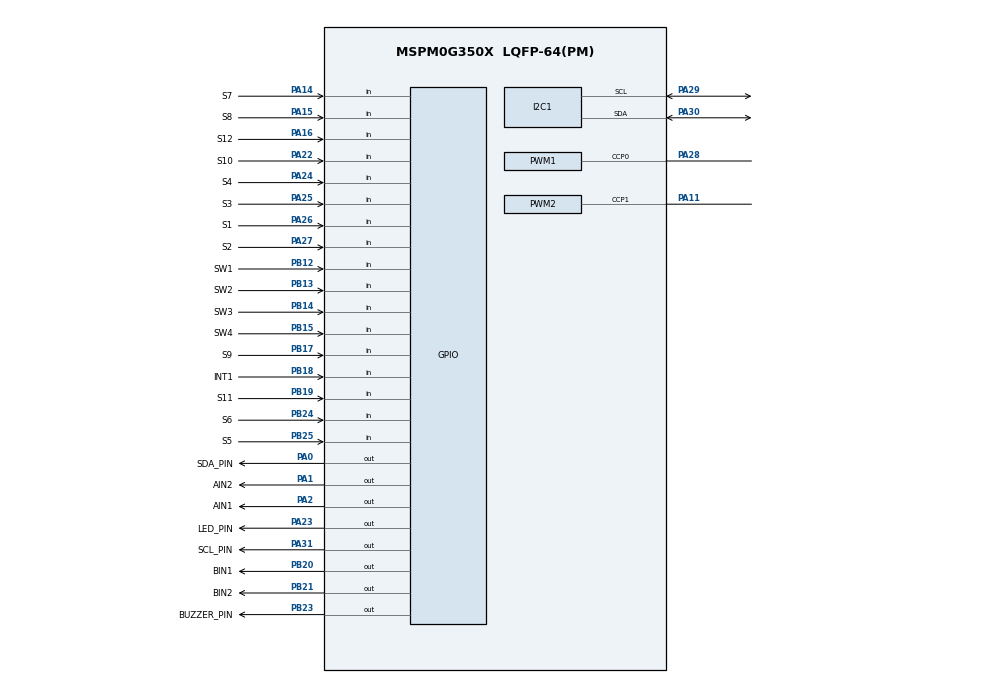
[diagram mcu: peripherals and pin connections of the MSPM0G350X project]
/**
 * @cliArgs --device "MSPM0G350X" --part "Default" --package "LQFP-64(PM)" --product "mspm0_sdk@2.11.00.07"
 * @versions {"tool":"1.26.2+4477"}
 */

/**
 * Import the modules used in this configuration.
 */
const GPIO   = scripting.addModule("/ti/driverlib/GPIO", {}, false);
const GPIO1  = GPIO.addInstance();
const GPIO2  = GPIO.addInstance();
const GPIO3  = GPIO.addInstance();
const GPIO4  = GPIO.addInstance();
const GPIO5  = GPIO.addInstance();
const GPIO7  = GPIO.addInstance();
const GPIO8  = GPIO.addInstance();
const I2C    = scripting.addModule("/ti/driverlib/I2C", {}, false);
const I2C1   = I2C.addInstance();
const PWM    = scripting.addModule("/ti/driverlib/PWM", {}, false);
const PWM1   = PWM.addInstance();
const PWM2   = PWM.addInstance();
const SYSCTL = scripting.addModule("/ti/driverlib/SYSCTL");

/**
 * Write custom configuration values to the imported modules.
 */
GPIO1.$name                          = "LED";
GPIO1.associatedPins[0].$name        = "LED_PIN";
GPIO1.associatedPins[0].pin.$assign  = "PA23";

const Board = scripting.addModule("/ti/driverlib/Board", {}, false);

GPIO2.$name                         = "BUZZER";
GPIO2.associatedPins[0].$name       = "BUZZER_PIN";
GPIO2.associatedPins[0].pin.$assign = "PB23";

GPIO3.$name                         = "OLED_SCL";
GPIO3.associatedPins[0].$name       = "SCL_PIN";
GPIO3.associatedPins[0].pin.$assign = "PA31";

GPIO4.$name                         = "OLED_SDA";
GPIO4.associatedPins[0].$name       = "SDA_PIN";
GPIO4.associatedPins[0].pin.$assign = "PA0";

GPIO5.$name = "GRAY";
GPIO5.associatedPins.create(12);
GPIO5.associatedPins[0].$name  = "S1";
GPIO5.associatedPins[0].direction = "INPUT";
GPIO5.associatedPins[0].pin.$assign = "PA26";
GPIO5.associatedPins[1].$name  = "S2";
GPIO5.associatedPins[1].direction = "INPUT";
GPIO5.associatedPins[1].pin.$assign = "PA27";
GPIO5.associatedPins[2].$name  = "S3";
GPIO5.associatedPins[2].direction = "INPUT";
GPIO5.associatedPins[2].pin.$assign = "PA25";
GPIO5.associatedPins[3].$name  = "S4";
GPIO5.associatedPins[3].direction = "INPUT";
GPIO5.associatedPins[3].pin.$assign = "PA24";
GPIO5.associatedPins[4].$name  = "S5";
GPIO5.associatedPins[4].direction = "INPUT";
GPIO5.associatedPins[4].pin.$assign = "PB25";
GPIO5.associatedPins[5].$name  = "S6";
GPIO5.associatedPins[5].direction = "INPUT";
GPIO5.associatedPins[5].pin.$assign = "PB24";
GPIO5.associatedPins[6].$name  = "S7";
GPIO5.associatedPins[6].direction = "INPUT";
GPIO5.associatedPins[6].pin.$assign = "PA14";
GPIO5.associatedPins[7].$name  = "S8";
GPIO5.associatedPins[7].direction = "INPUT";
GPIO5.associatedPins[7].pin.$assign = "PA15";
GPIO5.associatedPins[8].$name  = "S9";
GPIO5.associatedPins[8].direction = "INPUT";
GPIO5.associatedPins[8].pin.$assign = "PB17";
GPIO5.associatedPins[9].$name  = "S10";
GPIO5.associatedPins[9].direction = "INPUT";
GPIO5.associatedPins[9].pin.$assign = "PA22";
GPIO5.associatedPins[10].$name = "S11";
GPIO5.associatedPins[10].direction = "INPUT";
GPIO5.associatedPins[10].pin.$assign = "PB19";
GPIO5.associatedPins[11].$name = "S12";
GPIO5.associatedPins[11].direction = "INPUT";
GPIO5.associatedPins[11].pin.$assign = "PA16";

GPIO7.$name = "KEY";
GPIO7.associatedPins.create(4);
GPIO7.associatedPins[0].$name = "SW1";
GPIO7.associatedPins[0].direction = "INPUT";
GPIO7.associatedPins[0].internalResistor = "PULL_UP";
GPIO7.associatedPins[0].pin.$assign = "PB12";
GPIO7.associatedPins[1].$name = "SW2";
GPIO7.associatedPins[1].direction = "INPUT";
GPIO7.associatedPins[1].internalResistor = "PULL_UP";
GPIO7.associatedPins[1].pin.$assign = "PB13";
GPIO7.associatedPins[2].$name = "SW3";
GPIO7.associatedPins[2].direction = "INPUT";
GPIO7.associatedPins[2].internalResistor = "PULL_UP";
GPIO7.associatedPins[2].pin.$assign = "PB14";
GPIO7.associatedPins[3].$name = "SW4";
GPIO7.associatedPins[3].direction = "INPUT";
GPIO7.associatedPins[3].internalResistor = "PULL_UP";
GPIO7.associatedPins[3].pin.$assign = "PB15";

const GPIO6 = GPIO.addInstance();
GPIO6.$name = "MOTOR_DIR";
GPIO6.associatedPins.create(4);
GPIO6.associatedPins[0].$name = "AIN1";
GPIO6.associatedPins[0].pin.$assign = "PA2";
GPIO6.associatedPins[1].$name = "AIN2";
GPIO6.associatedPins[1].pin.$assign = "PA1";
GPIO6.associatedPins[2].$name = "BIN1";
GPIO6.associatedPins[2].pin.$assign = "PB20";
GPIO6.associatedPins[3].$name = "BIN2";
GPIO6.associatedPins[3].pin.$assign = "PB21";

PWM1.$name = "MOTOR_PWMA";
PWM1.timerCount = 1600;
PWM1.dutyArgs = "[50,0,0,0]";
PWM1.clockDivider = 1;
PWM1.clockPrescale = 1;
PWM1.ccIndex = [0];
PWM1.pwmMode = "EDGE_ALIGN_UP";
PWM1.peripheral.$assign = "TIMG7";
PWM1.peripheral.ccp0Pin.$assign = "PA28";
PWM1.PWM_CHANNEL_0.dutyCycle = 0;

PWM2.$name = "MOTOR_PWMB";
PWM2.timerCount = 1600;
PWM2.dutyArgs = "[0,50,0,0]";
PWM2.clockDivider = 1;
PWM2.clockPrescale = 1;
PWM2.ccIndex = [1];
PWM2.pwmMode = "EDGE_ALIGN_UP";
PWM2.peripheral.$assign = "TIMA1";
PWM2.peripheral.ccp1Pin.$assign = "PA11";
PWM2.PWM_CHANNEL_1.dutyCycle = 0;

I2C1.$name                     = "IMU_I2C";
I2C1.basicEnableController     = true;
I2C1.basicControllerBusSpeed   = 400000;
I2C1.peripheral.sclPin.$assign = "PA29";
I2C1.peripheral.sdaPin.$assign = "PA30";

GPIO8.$name                           = "IMU_INT1";
GPIO8.associatedPins[0].$name         = "INT1";
GPIO8.associatedPins[0].direction     = "INPUT";
GPIO8.associatedPins[0].interruptEn   = true;
GPIO8.associatedPins[0].interruptPriority = "3";
GPIO8.associatedPins[0].polarity      = "RISE";
GPIO8.associatedPins[0].pin.$assign   = "PB18";

SYSCTL.forceDefaultClkConfig = true;

/**
 * Pinmux solution for unlocked pins/peripherals. This ensures that minor changes to the automatic solver in a future
 * version of the tool will not impact the pinmux you originally saw.  These lines can be completely deleted in order to
 * re-solve from scratch.
 */
Board.peripheral.$suggestSolution          = "DEBUGSS";
Board.peripheral.swclkPin.$suggestSolution = "PA20";
Board.peripheral.swdioPin.$suggestSolution = "PA19";
I2C1.peripheral.$suggestSolution           = "I2C1";
I2C1.peripheral.sdaPin.$suggestSolution    = "PA30";
I2C1.peripheral.sclPin.$suggestSolution    = "PA29";
SYSCTL.peripheral.$suggestSolution         = "SYSCTL";
